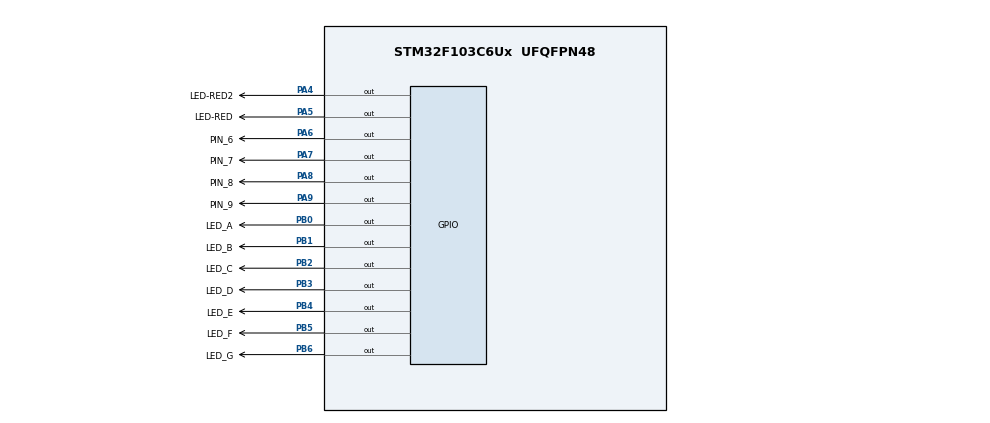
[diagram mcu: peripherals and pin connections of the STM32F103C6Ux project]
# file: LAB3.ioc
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Mcu.Family=STM32F1
Mcu.Name=STM32F103C6Ux
Mcu.Package=UFQFPN48
NVIC.PriorityGroup=NVIC_PRIORITYGROUP_4
NVIC.TIM2_IRQn=true\:0\:0\:false\:false\:true\:true\:true
PA4.GPIO_Label=LED-RED2
PA4.Signal=GPIO_Output
PA5.GPIO_Label=LED-RED
PA5.Signal=GPIO_Output
PA6.GPIO_Label=PIN_6
PA6.Signal=GPIO_Output
PA7.GPIO_Label=PIN_7
PA7.Signal=GPIO_Output
PA8.GPIO_Label=PIN_8
PA8.Signal=GPIO_Output
PA9.GPIO_Label=PIN_9
PA9.Signal=GPIO_Output
PB0.GPIO_Label=LED_A
PB0.Signal=GPIO_Output
PB1.GPIO_Label=LED_B
PB1.Signal=GPIO_Output
PB2.GPIO_Label=LED_C
PB2.Signal=GPIO_Output
PB3.GPIO_Label=LED_D
PB3.Signal=GPIO_Output
PB4.GPIO_Label=LED_E
PB4.Signal=GPIO_Output
PB5.GPIO_Label=LED_F
PB5.Signal=GPIO_Output
PB6.GPIO_Label=LED_G
PB6.Signal=GPIO_Output
ProjectManager.HeapSize=0x200
ProjectManager.StackSize=0x400
ProjectManager.TargetToolchain=STM32CubeIDE
RCC.APB1Freq_Value=8000000
RCC.APB2Freq_Value=8000000
TIM2.Period=9
TIM2.Prescaler=7999
VP_SYS_VS_ND.Mode=No_Debug
VP_TIM2_VS_ClockSourceINT.Mode=Internal
board=custom

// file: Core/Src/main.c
/* USER CODE BEGIN Header */
/**
  ******************************************************************************
  * @file           : main.c
  * @brief          : Main program body
  ******************************************************************************
  * @attention
  *
  * <h2><center>&copy; Copyright (c) 2024 STMicroelectronics.
  * All rights reserved.</center></h2>
  *
  * This software component is licensed by ST under BSD 3-Clause license,
  * the "License"; You may not use this file except in compliance with the
  * License. You may obtain a copy of the License at:
  *                        opensource.org/licenses/BSD-3-Clause
  *
  ******************************************************************************
  */
/* USER CODE END Header */
#include "main.h"
#include<software_timer.h>
#include "scheduler.h"

TIM_HandleTypeDef htim2;

void SystemClock_Config(void);
static void MX_GPIO_Init(void);
static void MX_TIM2_Init(void);

void clear7SEG() {
    HAL_GPIO_WritePin(GPIOB, LED_A_Pin | LED_B_Pin | LED_C_Pin | LED_D_Pin | LED_E_Pin | LED_F_Pin | LED_G_Pin, GPIO_PIN_SET);
}

void display7SEG(int num) {
    clear7SEG();

    switch(num) {
        case 0:
            HAL_GPIO_WritePin(GPIOB, LED_A_Pin | LED_B_Pin | LED_C_Pin | LED_D_Pin | LED_E_Pin | LED_F_Pin, GPIO_PIN_RESET);
            break;
        case 1:
            HAL_GPIO_WritePin(GPIOB, LED_B_Pin | LED_C_Pin, GPIO_PIN_RESET);
            break;
        case 2:
            HAL_GPIO_WritePin(GPIOB, LED_A_Pin | LED_B_Pin | LED_D_Pin | LED_E_Pin | LED_G_Pin, GPIO_PIN_RESET);
            break;
        case 3:
            HAL_GPIO_WritePin(GPIOB, LED_A_Pin | LED_B_Pin | LED_C_Pin | LED_D_Pin | LED_G_Pin, GPIO_PIN_RESET);
            break;
        case 4:
            HAL_GPIO_WritePin(GPIOB, LED_B_Pin | LED_C_Pin | LED_F_Pin | LED_G_Pin, GPIO_PIN_RESET);
            break;
        case 5:
            HAL_GPIO_WritePin(GPIOB, LED_A_Pin | LED_C_Pin | LED_D_Pin | LED_F_Pin | LED_G_Pin, GPIO_PIN_RESET);
            break;
        case 6:
            HAL_GPIO_WritePin(GPIOB, LED_A_Pin | LED_C_Pin | LED_D_Pin | LED_E_Pin | LED_F_Pin | LED_G_Pin, GPIO_PIN_RESET);
            break;
        case 7:
            HAL_GPIO_WritePin(GPIOB, LED_A_Pin | LED_B_Pin | LED_C_Pin, GPIO_PIN_RESET);
            break;
        case 8:
            HAL_GPIO_WritePin(GPIOB, LED_A_Pin | LED_B_Pin | LED_C_Pin | LED_D_Pin | LED_E_Pin | LED_F_Pin | LED_G_Pin, GPIO_PIN_RESET);
            break;
        case 9:
            HAL_GPIO_WritePin(GPIOB, LED_A_Pin | LED_B_Pin | LED_C_Pin | LED_D_Pin | LED_F_Pin | LED_G_Pin, GPIO_PIN_RESET);
            break;
        default:
            break;
    }
}

const int MAX_LED_MATRIX = 4;
int index_led = 0;
int led_buffer[4] = {1,2,3,4};

void update7SEG(int index) {
	switch(index) {
		case 0:
			display7SEG(led_buffer[0]);
			HAL_GPIO_WritePin(GPIOA, GPIO_PIN_6, GPIO_PIN_RESET);
			HAL_GPIO_WritePin(GPIOA, GPIO_PIN_7 | GPIO_PIN_8 | GPIO_PIN_9, GPIO_PIN_SET);
			break;
		case 1:
			display7SEG(led_buffer[1]);
			HAL_GPIO_WritePin(GPIOA, GPIO_PIN_7, GPIO_PIN_RESET);
			HAL_GPIO_WritePin(GPIOA, GPIO_PIN_6 | GPIO_PIN_8 | GPIO_PIN_9, GPIO_PIN_SET);
			break;
		case 2:
			display7SEG(led_buffer[2]);
			HAL_GPIO_WritePin(GPIOA, GPIO_PIN_8, GPIO_PIN_RESET);
			HAL_GPIO_WritePin(GPIOA, GPIO_PIN_6 | GPIO_PIN_7 | GPIO_PIN_9, GPIO_PIN_SET);
			break;
		case 3:
			display7SEG(led_buffer[3]);
			HAL_GPIO_WritePin(GPIOA, GPIO_PIN_9, GPIO_PIN_RESET);
			HAL_GPIO_WritePin(GPIOA, GPIO_PIN_6 | GPIO_PIN_7 | GPIO_PIN_8, GPIO_PIN_SET);
			break;
		default:
			break;
	}
}

void updateClockBuffer(int hour, int minute) {
	if(hour / 10 == 0) {
		led_buffer[0] = 0;
		led_buffer[1] = hour;
	} else {
		led_buffer[0] = hour / 10;
		led_buffer[1] = hour % 10;
	}

	if(minute / 10 == 0) {
		led_buffer[2] = 0;
		led_buffer[3] = minute;
	} else {
		led_buffer[2] = minute / 10;
		led_buffer[3] = minute % 10;
	}
}
void LedBlinky(){
	HAL_GPIO_TogglePin(LED_RED_GPIO_Port, LED_RED_Pin);
}
void DoubleDot(){
	HAL_GPIO_TogglePin(LED_RED2_GPIO_Port, LED_RED2_Pin);
}
void UpdateTimer(){
	static int hour = 2, minute = 10, second = 50;

	second++;
	if (second > 60) {
		second = 0;
		minute++;
	}

	if (minute >= 60) {
		minute = 0;
		hour++;
	}

	if (hour >= 24) {
		hour = 0;
	}

	updateClockBuffer(hour, minute);
}
void task_update7SEG(){
	static int index = 0;
	update7SEG(index++);
	if (index > 3){
		index = 0;
	}

}
int main(void)
{

  /* MCU Configuration--------------------------------------------------------*/

  /* Reset of all peripherals, Initializes the Flash interface and the Systick. */
  HAL_Init();

  /* Configure the system clock */
  SystemClock_Config();

  /* Initialize all configured peripherals */
  MX_GPIO_Init();
  MX_TIM2_Init();
  /* USER CODE BEGIN 2 */
  HAL_TIM_Base_Start_IT (& htim2 ) ;
  /* USER CODE END 2 */

  /* Infinite loop */
  /* USER CODE BEGIN WHILE */
  //Exercise 2
    int index = 0;
    SCH_Add_Task(LedBlinky, 0, 100);
    SCH_Add_Task(DoubleDot, 0, 50);
    SCH_Add_Task(UpdateTimer, 100, 100);
    SCH_Add_Task(task_update7SEG, 0, 25);
    while (1)
    {
      /* USER CODE END WHILE */
      /* USER CODE BEGIN 3 */
  		SCH_Dispatch_Tasks();
    }

  //Exercise 6-7-8
    /*
  setTimer(0,1000);
  setTimer(1,1000);
  int index = 0;
  int hour = 2, minute = 10, second = 50;

  while (1)
  {
    /* USER CODE END WHILE */
    /* USER CODE BEGIN 3 */
	/*	if(isTimerExpired(0)) {
			setTimer(0,1000);
			HAL_GPIO_TogglePin(LED_RED_GPIO_Port, LED_RED_Pin);
			HAL_GPIO_TogglePin(LED_RED2_GPIO_Port, LED_RED2_Pin);
		 }

		 if(isTimerExpired(1)) {
		     setTimer(1,1000);
		     second++;
		     if(second > 60) {
		     	 second = 0;
		     	 minute++;
		     }

		     if(minute >= 60) {
		     	 minute = 0;
		     	 hour++;
		     }

		     if(hour >= 24) {
		     	 hour = 0;
		     }

		     updateClockBuffer(hour, minute);
		     update7SEG(index++);
		 }
		 	if(index > 3) {
		 		index = 0;
		 	}
  } */
  /* USER CODE END 3 */
}
void HAL_TIM_PeriodElapsedCallback(TIM_HandleTypeDef *htim) {
		 SCH_Update(); // Update task counters and flags
}
void SystemClock_Config(void)
{
  RCC_OscInitTypeDef RCC_OscInitStruct = {0};
  RCC_ClkInitTypeDef RCC_ClkInitStruct = {0};

  /** Initializes the RCC Oscillators according to the specified parameters
  * in the RCC_OscInitTypeDef structure.
  */
  RCC_OscInitStruct.OscillatorType = RCC_OSCILLATORTYPE_HSI;
  RCC_OscInitStruct.HSIState = RCC_HSI_ON;
  RCC_OscInitStruct.HSICalibrationValue = RCC_HSICALIBRATION_DEFAULT;
  RCC_OscInitStruct.PLL.PLLState = RCC_PLL_NONE;
  if (HAL_RCC_OscConfig(&RCC_OscInitStruct) != HAL_OK)
  {
    Error_Handler();
  }
  /** Initializes the CPU, AHB and APB buses clocks
  */
  RCC_ClkInitStruct.ClockType = RCC_CLOCKTYPE_HCLK|RCC_CLOCKTYPE_SYSCLK
                              |RCC_CLOCKTYPE_PCLK1|RCC_CLOCKTYPE_PCLK2;
  RCC_ClkInitStruct.SYSCLKSource = RCC_SYSCLKSOURCE_HSI;
  RCC_ClkInitStruct.AHBCLKDivider = RCC_SYSCLK_DIV1;
  RCC_ClkInitStruct.APB1CLKDivider = RCC_HCLK_DIV1;
  RCC_ClkInitStruct.APB2CLKDivider = RCC_HCLK_DIV1;

  if (HAL_RCC_ClockConfig(&RCC_ClkInitStruct, FLASH_LATENCY_0) != HAL_OK)
  {
    Error_Handler();
  }
}

static void MX_TIM2_Init(void)
{

  TIM_ClockConfigTypeDef sClockSourceConfig = {0};
  TIM_MasterConfigTypeDef sMasterConfig = {0};

  htim2.Instance = TIM2;
  htim2.Init.Prescaler = 7999;
  htim2.Init.CounterMode = TIM_COUNTERMODE_UP;
  htim2.Init.Period = 9;
  htim2.Init.ClockDivision = TIM_CLOCKDIVISION_DIV1;
  htim2.Init.AutoReloadPreload = TIM_AUTORELOAD_PRELOAD_DISABLE;
  if (HAL_TIM_Base_Init(&htim2) != HAL_OK)
  {
    Error_Handler();
  }
  sClockSourceConfig.ClockSource = TIM_CLOCKSOURCE_INTERNAL;
  if (HAL_TIM_ConfigClockSource(&htim2, &sClockSourceConfig) != HAL_OK)
  {
    Error_Handler();
  }
  sMasterConfig.MasterOutputTrigger = TIM_TRGO_RESET;
  sMasterConfig.MasterSlaveMode = TIM_MASTERSLAVEMODE_DISABLE;
  if (HAL_TIMEx_MasterConfigSynchronization(&htim2, &sMasterConfig) != HAL_OK)
  {
    Error_Handler();
  }

}

static void MX_GPIO_Init(void)
{
  GPIO_InitTypeDef GPIO_InitStruct = {0};

  /* GPIO Ports Clock Enable */
  __HAL_RCC_GPIOA_CLK_ENABLE();
  __HAL_RCC_GPIOB_CLK_ENABLE();

  /*Configure GPIO pin Output Level */
  HAL_GPIO_WritePin(GPIOA, LED_RED2_Pin|LED_RED_Pin|PIN_6_Pin|PIN_7_Pin
                          |PIN_8_Pin|PIN_9_Pin, GPIO_PIN_RESET);

  /*Configure GPIO pin Output Level */
  HAL_GPIO_WritePin(GPIOB, LED_A_Pin|LED_B_Pin|LED_C_Pin|LED_D_Pin
                          |LED_E_Pin|LED_F_Pin|LED_G_Pin, GPIO_PIN_RESET);

  /*Configure GPIO pins : LED_RED2_Pin LED_RED_Pin PIN_6_Pin PIN_7_Pin
                           PIN_8_Pin PIN_9_Pin */
  GPIO_InitStruct.Pin = LED_RED2_Pin|LED_RED_Pin|PIN_6_Pin|PIN_7_Pin
                          |PIN_8_Pin|PIN_9_Pin;
  GPIO_InitStruct.Mode = GPIO_MODE_OUTPUT_PP;
  GPIO_InitStruct.Pull = GPIO_NOPULL;
  GPIO_InitStruct.Speed = GPIO_SPEED_FREQ_LOW;
  HAL_GPIO_Init(GPIOA, &GPIO_InitStruct);

  /*Configure GPIO pins : LED_A_Pin LED_B_Pin LED_C_Pin LED_D_Pin
                           LED_E_Pin LED_F_Pin LED_G_Pin */
  GPIO_InitStruct.Pin = LED_A_Pin|LED_B_Pin|LED_C_Pin|LED_D_Pin
                          |LED_E_Pin|LED_F_Pin|LED_G_Pin;
  GPIO_InitStruct.Mode = GPIO_MODE_OUTPUT_PP;
  GPIO_InitStruct.Pull = GPIO_NOPULL;
  GPIO_InitStruct.Speed = GPIO_SPEED_FREQ_LOW;
  HAL_GPIO_Init(GPIOB, &GPIO_InitStruct);

}

void Error_Handler(void)
{
  __disable_irq();
  while (1)
  {
  }
}

/************************ (C) COPYRIGHT STMicroelectronics *****END OF FILE****/
